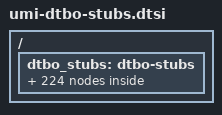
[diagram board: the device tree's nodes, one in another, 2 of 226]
// SPDX-License-Identifier: BSD-3-Clause
/*
 * umi-dtbo-stubs.dtsi — 自动生成，别手改（重新生成见 scripts/gen-dtbo-stubs.py）
 *
 * 为什么需要这个：
 *   这台机器的 ABL 在跳转前会把 dtbo 分区里的 29 个 overlay 打到 boot.img 的
 *   base DTB 上。每个 overlay 用 &label 指定目标节点（libfdt 按 __symbols__ 解析），
 *   overlay 打不上 ABL 就静默退回 fastboot —— 现象是 Booting OKAY 之后什么都不说。
 *   原厂 base DTB 有 1672 个 label，overlay 要的 241 个全都在；
 *   主线 DTB 只有 577 个，且命名体系不同（uart12 / ufs_mem_hc / usb_1 …）。
 *
 *   所以这里给 overlay 要的每个 label 建一个空的占位节点：
 *   overlay 就有了能打上去的目标，而被它写进去的下游属性落在占位节点上，
 *   对主线内核毫无影响（没有 compatible，也没有驱动会绑定）。
 */

/ {
	dtbo_stubs: dtbo-stubs {
		#address-cells = <1>;
		#size-cells = <0>;
		/* 没有 compatible：确保 of_platform_populate 不会给它们建设备 */
		BOB: stub-0 { reg = <0>; };
		L10A: stub-1 { reg = <1>; };
		L10C: stub-2 { reg = <2>; };
		L11C: stub-3 { reg = <3>; };
		L13A: stub-4 { reg = <4>; };
		L14A: stub-5 { reg = <5>; };
		L1C: stub-6 { reg = <6>; };
		L2C: stub-7 { reg = <7>; };
		L3C: stub-8 { reg = <8>; };
		L4C: stub-9 { reg = <9>; };
		L5C: stub-10 { reg = <10>; };
		L7A: stub-11 { reg = <11>; };
		L7C: stub-12 { reg = <12>; };
		L8C: stub-13 { reg = <13>; };
		S4A: stub-14 { reg = <14>; };
		S5A: stub-15 { reg = <15>; };
		S8C: stub-16 { reg = <16>; };
		arch_timer: stub-17 { reg = <17>; };
		audio_apr: stub-18 { reg = <18>; };
		aw8697_gpio_int: stub-19 { reg = <19>; };
		aw8697_gpio_reset: stub-20 { reg = <20>; };
		aw8697_gpio_reset_output_high: stub-21 { reg = <21>; };
		bolero: stub-22 { reg = <22>; };
		bt_en_sleep: stub-23 { reg = <23>; };
		cam_cci0: stub-24 { reg = <24>; };
		cam_cci1: stub-25 { reg = <25>; };
		cam_sensor_active_3: stub-26 { reg = <26>; };
		cam_sensor_active_6dofleft: stub-27 { reg = <27>; };
		cam_sensor_active_6dofright: stub-28 { reg = <28>; };
		cam_sensor_active_rear: stub-29 { reg = <29>; };
		cam_sensor_active_rear_aux: stub-30 { reg = <30>; };
		cam_sensor_active_rgbleft: stub-31 { reg = <31>; };
		cam_sensor_active_rst2: stub-32 { reg = <32>; };
		cam_sensor_mclk0_active: stub-33 { reg = <33>; };
		cam_sensor_mclk0_suspend: stub-34 { reg = <34>; };
		cam_sensor_mclk1_active: stub-35 { reg = <35>; };
		cam_sensor_mclk1_suspend: stub-36 { reg = <36>; };
		cam_sensor_mclk2_active: stub-37 { reg = <37>; };
		cam_sensor_mclk2_suspend: stub-38 { reg = <38>; };
		cam_sensor_mclk3_active: stub-39 { reg = <39>; };
		cam_sensor_mclk3_suspend: stub-40 { reg = <40>; };
		cam_sensor_mclk4_active: stub-41 { reg = <41>; };
		cam_sensor_mclk4_suspend: stub-42 { reg = <42>; };
		cam_sensor_mclk5_active: stub-43 { reg = <43>; };
		cam_sensor_mclk5_suspend: stub-44 { reg = <44>; };
		cam_sensor_mclk6_active: stub-45 { reg = <45>; };
		cam_sensor_mclk6_suspend: stub-46 { reg = <46>; };
		cam_sensor_suspend_3: stub-47 { reg = <47>; };
		cam_sensor_suspend_6dofleft: stub-48 { reg = <48>; };
		cam_sensor_suspend_6dofright: stub-49 { reg = <49>; };
		cam_sensor_suspend_rear: stub-50 { reg = <50>; };
		cam_sensor_suspend_rear_aux: stub-51 { reg = <51>; };
		cam_sensor_suspend_rgbleft: stub-52 { reg = <52>; };
		cam_sensor_suspend_rst2: stub-53 { reg = <53>; };
		cci0_active: stub-54 { reg = <54>; };
		cci1_active: stub-55 { reg = <55>; };
		cci3_active: stub-56 { reg = <56>; };
		clock_camcc: stub-57 { reg = <57>; };
		clock_rpmh: stub-58 { reg = <58>; };
		cpu4_isolate: stub-59 { reg = <59>; };
		cpu5_isolate: stub-60 { reg = <60>; };
		cpu6_isolate: stub-61 { reg = <61>; };
		cpu7_isolate: stub-62 { reg = <62>; };
		cs35l41_int_speaker: stub-63 { reg = <63>; };
		cs35l41_int_speaker_rcv: stub-64 { reg = <64>; };
		dai_mi2s0: stub-65 { reg = <65>; };
		dai_mi2s2: stub-66 { reg = <66>; };
		disp_rdump_memory: stub-67 { reg = <67>; };
		eud: stub-68 { reg = <68>; };
		firmware: stub-69 { reg = <69>; };
		fsa4480: stub-70 { reg = <70>; };
		ipa_hw: stub-71 { reg = <71>; };
		kona_snd: stub-72 { reg = <72>; };
		lpass_audio_hw_vote: stub-73 { reg = <73>; };
		lpass_core_hw_vote: stub-74 { reg = <74>; };
		lt9611_pins: stub-75 { reg = <75>; };
		maxim_ds28e16: stub-76 { reg = <76>; };
		mdm0: stub-77 { reg = <77>; };
		mdss_dsi0_pll: stub-78 { reg = <78>; };
		mdss_dsi1_pll: stub-79 { reg = <79>; };
		mdss_dsi_phy0: stub-80 { reg = <80>; };
		mdss_dsi_phy1: stub-81 { reg = <81>; };
		memtimer: stub-82 { reg = <82>; };
		mhi_0: stub-83 { reg = <83>; };
		modem_mmw_skin0: stub-84 { reg = <84>; };
		modem_mmw_skin1: stub-85 { reg = <85>; };
		modem_mmw_skin2: stub-86 { reg = <86>; };
		modem_skin: stub-87 { reg = <87>; };
		msm_gpu: stub-88 { reg = <88>; };
		nfc_clk_req_active: stub-89 { reg = <89>; };
		nfc_clk_req_suspend: stub-90 { reg = <90>; };
		nfc_enable_active: stub-91 { reg = <91>; };
		nfc_enable_suspend: stub-92 { reg = <92>; };
		nfc_int_active: stub-93 { reg = <93>; };
		nfc_int_suspend: stub-94 { reg = <94>; };
		pcie1_msi: stub-95 { reg = <95>; };
		pcie2_rp: stub-96 { reg = <96>; };
		pm8009_l1: stub-97 { reg = <97>; };
		pm8009_l2: stub-98 { reg = <98>; };
		pm8009_l3: stub-99 { reg = <99>; };
		pm8009_l4: stub-100 { reg = <100>; };
		pm8009_l5: stub-101 { reg = <101>; };
		pm8009_l6: stub-102 { reg = <102>; };
		pm8009_l7: stub-103 { reg = <103>; };
		pm8009_s2: stub-104 { reg = <104>; };
		pm8150_l10: stub-105 { reg = <105>; };
		pm8150_l13: stub-106 { reg = <106>; };
		pm8150_l14: stub-107 { reg = <107>; };
		pm8150_l16: stub-108 { reg = <108>; };
		pm8150_l17: stub-109 { reg = <109>; };
		pm8150_l2: stub-110 { reg = <110>; };
		pm8150_l5: stub-111 { reg = <111>; };
		pm8150_l6: stub-112 { reg = <112>; };
		pm8150_l7: stub-113 { reg = <113>; };
		pm8150_l9: stub-114 { reg = <114>; };
		pm8150_s4: stub-115 { reg = <115>; };
		pm8150_s5: stub-116 { reg = <116>; };
		pm8150_s6: stub-117 { reg = <117>; };
		pm8150a_bob: stub-118 { reg = <118>; };
		pm8150a_l1: stub-119 { reg = <119>; };
		pm8150a_l11: stub-120 { reg = <120>; };
		pm8150a_l2: stub-121 { reg = <121>; };
		pm8150a_l3: stub-122 { reg = <122>; };
		pm8150a_l4: stub-123 { reg = <123>; };
		pm8150a_l5: stub-124 { reg = <124>; };
		pm8150a_l6: stub-125 { reg = <125>; };
		pm8150a_l7: stub-126 { reg = <126>; };
		pm8150a_l8: stub-127 { reg = <127>; };
		pm8150a_l9: stub-128 { reg = <128>; };
		pm8150a_s8: stub-129 { reg = <129>; };
		pmx_ts_release: stub-130 { reg = <130>; };
		pri_mi2s_sck_active: stub-131 { reg = <131>; };
		pri_mi2s_sck_sleep: stub-132 { reg = <132>; };
		pri_mi2s_sd0_active: stub-133 { reg = <133>; };
		pri_mi2s_sd0_sleep: stub-134 { reg = <134>; };
		pri_mi2s_sd1_active: stub-135 { reg = <135>; };
		pri_mi2s_sd1_sleep: stub-136 { reg = <136>; };
		pri_mi2s_ws_active: stub-137 { reg = <137>; };
		pri_mi2s_ws_sleep: stub-138 { reg = <138>; };
		q6core: stub-139 { reg = <139>; };
		qseecom_mem: stub-140 { reg = <140>; };
		qupv3_se0_i2c: stub-141 { reg = <141>; };
		qupv3_se11_i2c: stub-142 { reg = <142>; };
		qupv3_se12_2uart: stub-143 { reg = <143>; };
		qupv3_se13_i2c: stub-144 { reg = <144>; };
		qupv3_se15_i2c: stub-145 { reg = <145>; };
		qupv3_se16_i2c: stub-146 { reg = <146>; };
		qupv3_se17_i2c: stub-147 { reg = <147>; };
		qupv3_se1_i2c: stub-148 { reg = <148>; };
		qupv3_se2_2uart: stub-149 { reg = <149>; };
		qupv3_se2_i2c: stub-150 { reg = <150>; };
		qupv3_se2_spi: stub-151 { reg = <151>; };
		qupv3_se3_i2c: stub-152 { reg = <152>; };
		qupv3_se4_spi: stub-153 { reg = <153>; };
		qupv3_se4_spi_active: stub-154 { reg = <154>; };
		qupv3_se4_spi_sleep: stub-155 { reg = <155>; };
		qupv3_se5_4uart: stub-156 { reg = <156>; };
		qupv3_se6_4uart: stub-157 { reg = <157>; };
		qupv3_se8_i2c: stub-158 { reg = <158>; };
		qupv3_se9_i2c: stub-159 { reg = <159>; };
		reserved_memory: stub-160 { reg = <160>; };
		sdc2_clk_off: stub-161 { reg = <161>; };
		sdc2_clk_on: stub-162 { reg = <162>; };
		sdc2_cmd_off: stub-163 { reg = <163>; };
		sdc2_cmd_on: stub-164 { reg = <164>; };
		sdc2_data_off: stub-165 { reg = <165>; };
		sdc2_data_on: stub-166 { reg = <166>; };
		sde_dp: stub-167 { reg = <167>; };
		sde_dp_usbplug_cc_active: stub-168 { reg = <168>; };
		sde_dp_usbplug_cc_suspend: stub-169 { reg = <169>; };
		sde_dsi1_active: stub-170 { reg = <170>; };
		sde_dsi1_suspend: stub-171 { reg = <171>; };
		sde_dsi_active: stub-172 { reg = <172>; };
		sde_dsi_suspend: stub-173 { reg = <173>; };
		sde_rscc: stub-174 { reg = <174>; };
		sde_te1_active: stub-175 { reg = <175>; };
		sde_te1_suspend: stub-176 { reg = <176>; };
		sde_te_active: stub-177 { reg = <177>; };
		sde_te_suspend: stub-178 { reg = <178>; };
		spkr_1_sd_n_active: stub-179 { reg = <179>; };
		spkr_1_sd_n_sleep: stub-180 { reg = <180>; };
		spkr_2_sd_n_active: stub-181 { reg = <181>; };
		spkr_2_sd_n_sleep: stub-182 { reg = <182>; };
		spmi_debug_bus: stub-183 { reg = <183>; };
		storage_cd: stub-184 { reg = <184>; };
		stub_codec: stub-185 { reg = <185>; };
		tdm_tert_rx: stub-186 { reg = <186>; };
		tdm_tert_tx: stub-187 { reg = <187>; };
		tert_mi2s_sck_active: stub-188 { reg = <188>; };
		tert_mi2s_sck_sleep: stub-189 { reg = <189>; };
		tert_mi2s_sd0_active: stub-190 { reg = <190>; };
		tert_mi2s_sd0_sleep: stub-191 { reg = <191>; };
		tert_mi2s_sd1_active: stub-192 { reg = <192>; };
		tert_mi2s_sd1_sleep: stub-193 { reg = <193>; };
		tert_mi2s_ws_active: stub-194 { reg = <194>; };
		tert_mi2s_ws_sleep: stub-195 { reg = <195>; };
		tert_tdm_clk_active: stub-196 { reg = <196>; };
		tert_tdm_clk_sleep: stub-197 { reg = <197>; };
		tert_tdm_din_active: stub-198 { reg = <198>; };
		tert_tdm_din_sleep: stub-199 { reg = <199>; };
		tert_tdm_dout_active: stub-200 { reg = <200>; };
		tert_tdm_dout_sleep: stub-201 { reg = <201>; };
		tert_tdm_ws_active: stub-202 { reg = <202>; };
		tert_tdm_ws_sleep: stub-203 { reg = <203>; };
		thermal_zones: stub-204 { reg = <204>; };
		titan_top_gdsc: stub-205 { reg = <205>; };
		ufs_phy_gdsc: stub-206 { reg = <206>; };
		ufshc_mem: stub-207 { reg = <207>; };
		ufsphy_mem: stub-208 { reg = <208>; };
		usb0: stub-209 { reg = <209>; };
		usb1: stub-210 { reg = <210>; };
		usb2_id_det_default: stub-211 { reg = <211>; };
		usb2_phy0: stub-212 { reg = <212>; };
		usb2_phy1: stub-213 { reg = <213>; };
		usb_nop_phy: stub-214 { reg = <214>; };
		usb_qmp_dp_phy: stub-215 { reg = <215>; };
		usb_qmp_phy: stub-216 { reg = <216>; };
		va_cdc_dma_0_tx: stub-217 { reg = <217>; };
		vendor: stub-218 { reg = <218>; };
		wcd938x_reset_active: stub-219 { reg = <219>; };
		wcd938x_reset_sleep: stub-220 { reg = <220>; };
		wdog: stub-221 { reg = <221>; };
		wil6210: stub-222 { reg = <222>; };
		wlan: stub-223 { reg = <223>; };
	};
};
